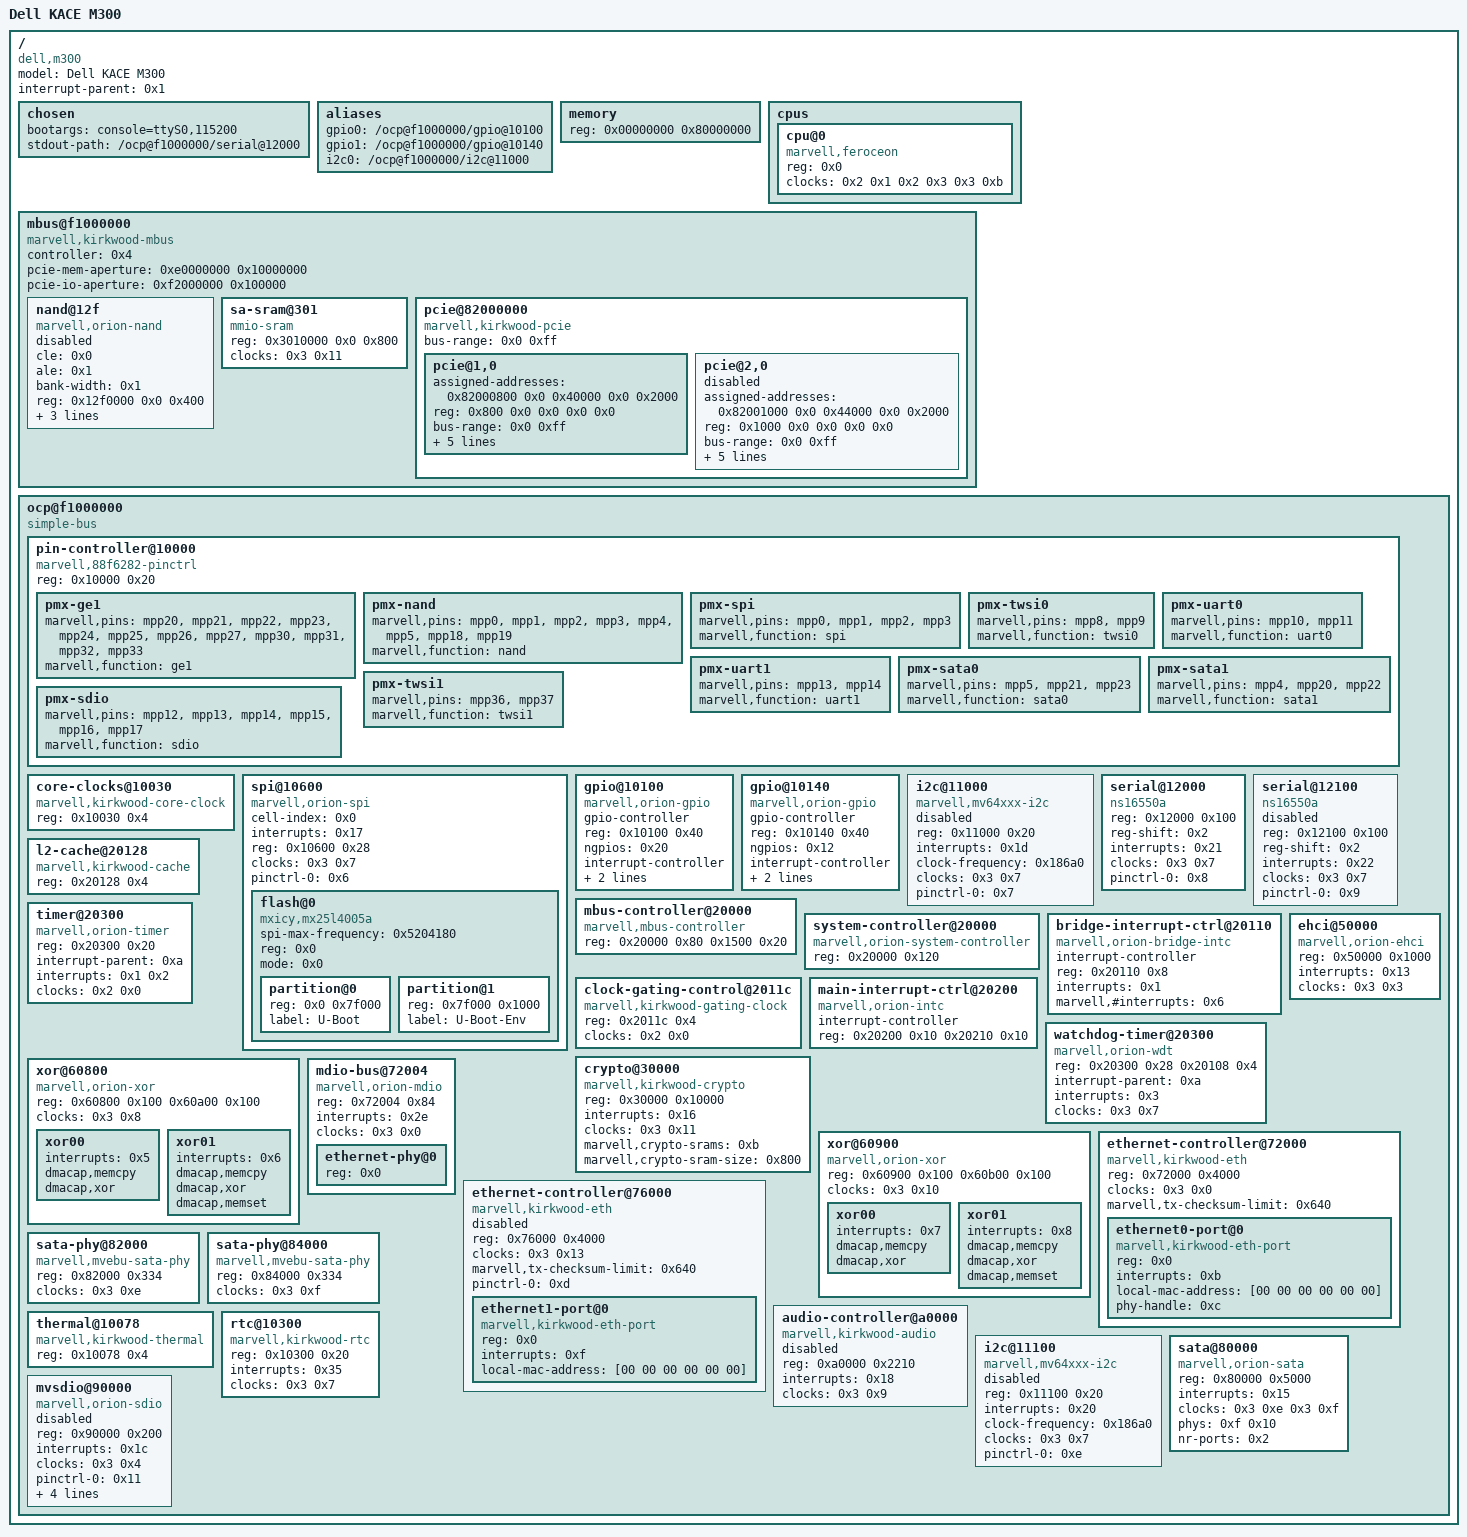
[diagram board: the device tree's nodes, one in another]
/dts-v1/;

/ {
        model = "Dell KACE M300";
        compatible = "dell,m300", "marvell,kirkwood-88f6282", "marvell,kirkwood";
        #address-cells = <0x1>;
        #size-cells = <0x1>;
        interrupt-parent = <0x1>;

        chosen {
                bootargs = "console=ttyS0,115200";
                stdout-path = "/ocp@f1000000/serial@12000";
        };

        aliases {
                gpio0 = "/ocp@f1000000/gpio@10100";
                gpio1 = "/ocp@f1000000/gpio@10140";
                i2c0 = "/ocp@f1000000/i2c@11000";
        };

        memory {
                device_type = "memory";
                reg = <0x00000000 0x80000000>;
        };

        cpus {
                #address-cells = <0x1>;
                #size-cells = <0x0>;

                cpu@0 {
                        device_type = "cpu";
                        compatible = "marvell,feroceon";
                        reg = <0x0>;
                        clocks = <0x2 0x1 0x2 0x3 0x3 0xb>;
                        clock-names = "cpu_clk", "ddrclk", "powersave";
                };
        };

        mbus@f1000000 {
                compatible = "marvell,kirkwood-mbus", "simple-bus";
                #address-cells = <0x2>;
                #size-cells = <0x1>;
                ranges = <0xf0010000 0x0 0xf1000000 0x100000 0x12f0000 0x0 0xf4000000 0x10000 0x3010000 0x0 0xf5000000 0x10000>;
                controller = <0x4>;
                pcie-mem-aperture = <0xe0000000 0x10000000>;
                pcie-io-aperture = <0xf2000000 0x100000>;

                nand@12f {
                        #address-cells = <0x1>;
                        #size-cells = <0x1>;
                        cle = <0x0>;
                        ale = <0x1>;
                        bank-width = <0x1>;
                        compatible = "marvell,orion-nand";
                        reg = <0x12f0000 0x0 0x400>;
                        chip-delay = <0x19>;
                        clocks = <0x3 0x7>;
                        pinctrl-0 = <0x5>;
                        pinctrl-names = "default";
                        status = "disabled";
                };

                sa-sram@301 {
                        compatible = "mmio-sram";
                        reg = <0x3010000 0x0 0x800>;
                        clocks = <0x3 0x11>;
                        #address-cells = <0x1>;
                        #size-cells = <0x1>;
                        phandle = <0xb>;
                };

                pcie@82000000 {
                        compatible = "marvell,kirkwood-pcie";
                        status = "okay";
                        device_type = "pci";
                        #address-cells = <0x3>;
                        #size-cells = <0x2>;
                        bus-range = <0x0 0xff>;
                        ranges = <0x82000000 0x0 0x40000 0xf0010000 0x40000 0x0 0x2000 0x82000000 0x0 0x44000 0xf0010000 0x44000 0x0 0x2000 0x82000000 0x0 0x80000 0xf0010000 0x80000 0x0 0x2000 0x82000000 0x1 0x0 0x4e80000 0x0 0x1 0x0 0x81000000 0x1 0x0 0x4e00000 0x0 0x1 0x0 0x82000000 0x2 0x0 0x4d80000 0x0 0x1 0x0 0x81000000 0x2 0x0 0x4d00000 0x0 0x1 0x0>;

                        pcie@1,0 {
                                device_type = "pci";
                                assigned-addresses = <0x82000800 0x0 0x40000 0x0 0x2000>;
                                reg = <0x800 0x0 0x0 0x0 0x0>;
                                #address-cells = <0x3>;
                                #size-cells = <0x2>;
                                #interrupt-cells = <0x1>;
                                ranges = <0x82000000 0x0 0x0 0x82000000 0x1 0x0 0x1 0x0 0x81000000 0x0 0x0 0x81000000 0x1 0x0 0x1 0x0>;
                                bus-range = <0x0 0xff>;
                                interrupt-map-mask = <0x0 0x0 0x0 0x0>;
                                interrupt-map = <0x0 0x0 0x0 0x0 0x1 0x9>;
                                marvell,pcie-port = <0x0>;
                                marvell,pcie-lane = <0x0>;
                                clocks = <0x3 0x2>;
                                status = "okay";
                        };

                        pcie@2,0 {
                                device_type = "pci";
                                assigned-addresses = <0x82001000 0x0 0x44000 0x0 0x2000>;
                                reg = <0x1000 0x0 0x0 0x0 0x0>;
                                #address-cells = <0x3>;
                                #size-cells = <0x2>;
                                #interrupt-cells = <0x1>;
                                ranges = <0x82000000 0x0 0x0 0x82000000 0x2 0x0 0x1 0x0 0x81000000 0x0 0x0 0x81000000 0x2 0x0 0x1 0x0>;
                                bus-range = <0x0 0xff>;
                                interrupt-map-mask = <0x0 0x0 0x0 0x0>;
                                interrupt-map = <0x0 0x0 0x0 0x0 0x1 0xa>;
                                marvell,pcie-port = <0x1>;
                                marvell,pcie-lane = <0x0>;
                                clocks = <0x3 0x12>;
                                status = "disabled";
                        };
                };
        };

        ocp@f1000000 {
                compatible = "simple-bus";
                ranges = <0x0 0xf1000000 0x100000>;
                #address-cells = <0x1>;
                #size-cells = <0x1>;

                pin-controller@10000 {
                        reg = <0x10000 0x20>;
                        compatible = "marvell,88f6282-pinctrl";

                        pmx-ge1 {
                                marvell,pins = "mpp20", "mpp21", "mpp22", "mpp23", "mpp24", "mpp25", "mpp26", "mpp27", "mpp30", "mpp31", "mpp32", "mpp33";
                                marvell,function = "ge1";
                                phandle = <0xd>;
                        };

                        pmx-nand {
                                marvell,pins = "mpp0", "mpp1", "mpp2", "mpp3", "mpp4", "mpp5", "mpp18", "mpp19";
                                marvell,function = "nand";
                                phandle = <0x5>;
                        };

                        pmx-spi {
                                marvell,pins = "mpp0", "mpp1", "mpp2", "mpp3";
                                marvell,function = "spi";
                                phandle = <0x6>;
                        };

                        pmx-twsi0 {
                                marvell,pins = "mpp8", "mpp9";
                                marvell,function = "twsi0";
                                phandle = <0x7>;
                        };

                        pmx-uart0 {
                                marvell,pins = "mpp10", "mpp11";
                                marvell,function = "uart0";
                                phandle = <0x8>;
                        };

                        pmx-uart1 {
                                marvell,pins = "mpp13", "mpp14";
                                marvell,function = "uart1";
                                phandle = <0x9>;
                        };

                        pmx-sata0 {
                                marvell,pins = "mpp5", "mpp21", "mpp23";
                                marvell,function = "sata0";
                        };

                        pmx-sata1 {
                                marvell,pins = "mpp4", "mpp20", "mpp22";
                                marvell,function = "sata1";
                        };

                        pmx-twsi1 {
                                marvell,pins = "mpp36", "mpp37";
                                marvell,function = "twsi1";
                                phandle = <0xe>;
                        };

                        pmx-sdio {
                                marvell,pins = "mpp12", "mpp13", "mpp14", "mpp15", "mpp16", "mpp17";
                                marvell,function = "sdio";
                                phandle = <0x11>;
                        };
                };

                core-clocks@10030 {
                        compatible = "marvell,kirkwood-core-clock";
                        reg = <0x10030 0x4>;
                        #clock-cells = <0x1>;
                        phandle = <0x2>;
                };

                spi@10600 {
                        compatible = "marvell,orion-spi";
                        #address-cells = <0x1>;
                        #size-cells = <0x0>;
                        cell-index = <0x0>;
                        interrupts = <0x17>;
                        reg = <0x10600 0x28>;
                        clocks = <0x3 0x7>;
                        pinctrl-0 = <0x6>;
                        pinctrl-names = "default";
                        status = "okay";

                        flash@0 {
                                #address-cells = <0x1>;
                                #size-cells = <0x1>;
                                compatible = "mxicy,mx25l4005a", "jedec,spi-nor";
                                spi-max-frequency = <0x5204180>;
                                reg = <0x0>;
                                mode = <0x0>;

                                partition@0 {
                                        reg = <0x0 0x7f000>;
                                        label = "U-Boot";
                                };

                                partition@1 {
                                        reg = <0x7f000 0x1000>;
                                        label = "U-Boot-Env";
                                };
                        };
                };

                gpio@10100 {
                        compatible = "marvell,orion-gpio";
                        #gpio-cells = <0x2>;
                        gpio-controller;
                        reg = <0x10100 0x40>;
                        ngpios = <0x20>;
                        interrupt-controller;
                        #interrupt-cells = <0x2>;
                        interrupts = <0x23 0x24 0x25 0x26>;
                        clocks = <0x3 0x7>;
                };

                gpio@10140 {
                        compatible = "marvell,orion-gpio";
                        #gpio-cells = <0x2>;
                        gpio-controller;
                        reg = <0x10140 0x40>;
                        ngpios = <0x12>;
                        interrupt-controller;
                        #interrupt-cells = <0x2>;
                        interrupts = <0x27 0x28 0x29>;
                        clocks = <0x3 0x7>;
                };

                i2c@11000 {
                        compatible = "marvell,mv64xxx-i2c";
                        reg = <0x11000 0x20>;
                        #address-cells = <0x1>;
                        #size-cells = <0x0>;
                        interrupts = <0x1d>;
                        clock-frequency = <0x186a0>;
                        clocks = <0x3 0x7>;
                        pinctrl-0 = <0x7>;
                        pinctrl-names = "default";
                        status = "disabled";
                };

                serial@12000 {
                        compatible = "ns16550a";
                        reg = <0x12000 0x100>;
                        reg-shift = <0x2>;
                        interrupts = <0x21>;
                        clocks = <0x3 0x7>;
                        pinctrl-0 = <0x8>;
                        pinctrl-names = "default";
                        status = "ok";
                };

                serial@12100 {
                        compatible = "ns16550a";
                        reg = <0x12100 0x100>;
                        reg-shift = <0x2>;
                        interrupts = <0x22>;
                        clocks = <0x3 0x7>;
                        pinctrl-0 = <0x9>;
                        pinctrl-names = "default";
                        status = "disabled";
                };

                mbus-controller@20000 {
                        compatible = "marvell,mbus-controller";
                        reg = <0x20000 0x80 0x1500 0x20>;
                        phandle = <0x4>;
                };

                system-controller@20000 {
                        compatible = "marvell,orion-system-controller";
                        reg = <0x20000 0x120>;
                };

                bridge-interrupt-ctrl@20110 {
                        compatible = "marvell,orion-bridge-intc";
                        interrupt-controller;
                        #interrupt-cells = <0x1>;
                        reg = <0x20110 0x8>;
                        interrupts = <0x1>;
                        marvell,#interrupts = <0x6>;
                        phandle = <0xa>;
                };

                clock-gating-control@2011c {
                        compatible = "marvell,kirkwood-gating-clock";
                        reg = <0x2011c 0x4>;
                        clocks = <0x2 0x0>;
                        #clock-cells = <0x1>;
                        phandle = <0x3>;
                };

                l2-cache@20128 {
                        compatible = "marvell,kirkwood-cache";
                        reg = <0x20128 0x4>;
                };

                main-interrupt-ctrl@20200 {
                        compatible = "marvell,orion-intc";
                        interrupt-controller;
                        #interrupt-cells = <0x1>;
                        reg = <0x20200 0x10 0x20210 0x10>;
                        phandle = <0x1>;
                };

                timer@20300 {
                        compatible = "marvell,orion-timer";
                        reg = <0x20300 0x20>;
                        interrupt-parent = <0xa>;
                        interrupts = <0x1 0x2>;
                        clocks = <0x2 0x0>;
                };

                watchdog-timer@20300 {
                        compatible = "marvell,orion-wdt";
                        reg = <0x20300 0x28 0x20108 0x4>;
                        interrupt-parent = <0xa>;
                        interrupts = <0x3>;
                        clocks = <0x3 0x7>;
                        status = "okay";
                };

                crypto@30000 {
                        compatible = "marvell,kirkwood-crypto";
                        reg = <0x30000 0x10000>;
                        reg-names = "regs";
                        interrupts = <0x16>;
                        clocks = <0x3 0x11>;
                        marvell,crypto-srams = <0xb>;
                        marvell,crypto-sram-size = <0x800>;
                        status = "okay";
                };

                ehci@50000 {
                        compatible = "marvell,orion-ehci";
                        reg = <0x50000 0x1000>;
                        interrupts = <0x13>;
                        clocks = <0x3 0x3>;
                        status = "okay";
                };

                xor@60800 {
                        compatible = "marvell,orion-xor";
                        reg = <0x60800 0x100 0x60a00 0x100>;
                        status = "okay";
                        clocks = <0x3 0x8>;

                        xor00 {
                                interrupts = <0x5>;
                                dmacap,memcpy;
                                dmacap,xor;
                        };

                        xor01 {
                                interrupts = <0x6>;
                                dmacap,memcpy;
                                dmacap,xor;
                                dmacap,memset;
                        };
                };

                xor@60900 {
                        compatible = "marvell,orion-xor";
                        reg = <0x60900 0x100 0x60b00 0x100>;
                        status = "okay";
                        clocks = <0x3 0x10>;

                        xor00 {
                                interrupts = <0x7>;
                                dmacap,memcpy;
                                dmacap,xor;
                        };

                        xor01 {
                                interrupts = <0x8>;
                                dmacap,memcpy;
                                dmacap,xor;
                                dmacap,memset;
                        };
                };

                ethernet-controller@72000 {
                        compatible = "marvell,kirkwood-eth";
                        #address-cells = <0x1>;
                        #size-cells = <0x0>;
                        reg = <0x72000 0x4000>;
                        clocks = <0x3 0x0>;
                        marvell,tx-checksum-limit = <0x640>;
                        status = "okay";

                        ethernet0-port@0 {
                                compatible = "marvell,kirkwood-eth-port";
                                reg = <0x0>;
                                interrupts = <0xb>;
                                local-mac-address = [00 00 00 00 00 00];
                                phy-handle = <0xc>;
                        };
                };

                mdio-bus@72004 {
                        compatible = "marvell,orion-mdio";
                        #address-cells = <0x1>;
                        #size-cells = <0x0>;
                        reg = <0x72004 0x84>;
                        interrupts = <0x2e>;
                        clocks = <0x3 0x0>;
                        status = "okay";

                        ethernet-phy@0 {
                                reg = <0x0>;
                                phandle = <0xc>;
                        };
                };

                ethernet-controller@76000 {
                        compatible = "marvell,kirkwood-eth";
                        #address-cells = <0x1>;
                        #size-cells = <0x0>;
                        reg = <0x76000 0x4000>;
                        clocks = <0x3 0x13>;
                        marvell,tx-checksum-limit = <0x640>;
                        pinctrl-0 = <0xd>;
                        pinctrl-names = "default";
                        status = "disabled";

                        ethernet1-port@0 {
                                compatible = "marvell,kirkwood-eth-port";
                                reg = <0x0>;
                                interrupts = <0xf>;
                                local-mac-address = [00 00 00 00 00 00];
                        };
                };

                sata-phy@82000 {
                        compatible = "marvell,mvebu-sata-phy";
                        reg = <0x82000 0x334>;
                        clocks = <0x3 0xe>;
                        clock-names = "sata";
                        #phy-cells = <0x0>;
                        status = "ok";
                        phandle = <0xf>;
                };

                sata-phy@84000 {
                        compatible = "marvell,mvebu-sata-phy";
                        reg = <0x84000 0x334>;
                        clocks = <0x3 0xf>;
                        clock-names = "sata";
                        #phy-cells = <0x0>;
                        status = "ok";
                        phandle = <0x10>;
                };

                audio-controller@a0000 {
                        compatible = "marvell,kirkwood-audio";
                        #sound-dai-cells = <0x0>;
                        reg = <0xa0000 0x2210>;
                        interrupts = <0x18>;
                        clocks = <0x3 0x9>;
                        clock-names = "internal";
                        status = "disabled";
                };

                thermal@10078 {
                        compatible = "marvell,kirkwood-thermal";
                        reg = <0x10078 0x4>;
                        status = "okay";
                };

                rtc@10300 {
                        compatible = "marvell,kirkwood-rtc", "marvell,orion-rtc";
                        reg = <0x10300 0x20>;
                        interrupts = <0x35>;
                        clocks = <0x3 0x7>;
                };

                i2c@11100 {
                        compatible = "marvell,mv64xxx-i2c";
                        reg = <0x11100 0x20>;
                        #address-cells = <0x1>;
                        #size-cells = <0x0>;
                        interrupts = <0x20>;
                        clock-frequency = <0x186a0>;
                        clocks = <0x3 0x7>;
                        pinctrl-0 = <0xe>;
                        pinctrl-names = "default";
                        status = "disabled";
                };

                sata@80000 {
                        compatible = "marvell,orion-sata";
                        reg = <0x80000 0x5000>;
                        interrupts = <0x15>;
                        clocks = <0x3 0xe 0x3 0xf>;
                        clock-names = <0x30003100>;
                        phys = <0xf 0x10>;
                        phy-names = "port0", "port1";
                        status = "okay";
                        nr-ports = <0x2>;
                };

                mvsdio@90000 {
                        compatible = "marvell,orion-sdio";
                        reg = <0x90000 0x200>;
                        interrupts = <0x1c>;
                        clocks = <0x3 0x4>;
                        pinctrl-0 = <0x11>;
                        pinctrl-names = "default";
                        bus-width = <0x4>;
                        cap-sdio-irq;
                        cap-sd-highspeed;
                        cap-mmc-highspeed;
                        status = "disabled";
                };
        };
};
